# CM41x_M0 register map
Vendor: Analog Devices; Series: CM41x_M0; File version: 1p0
CPU: CM0 r0p0, little endian, MPU, FPU, 4 interrupt priority bits
Registers are 32-bit, read-write, reset 0x0 unless marked. A register's access mark holds for its fields unless they carry their own. Offsets are from the block's base; [hi:lo] are bit positions; {n}, {i} and the like mark numbered series; 'fields as' and 'values as' point back to an identical list.

## DWT1 — Data watchpoint unit
Base 0xE0001000
0x00 DWT_CTRL reset 0x20000000
  [31:28] NUMCOMP ro — Number of comparators.
0x1C DWT_PCSR
  [31:0] EIASAMPLE ro — Execution instruction address sample
0x20 DWT_COMP0
  [31:0] COMP range 0x00000000..0xFFFFFFFF — PC compare value
0x24 DWT_MASK0
  [3:0] MASK range 0x00000000..0x0000000F — Data Mask
0x28 DWT_FUNCTION0
  [3:0] FUNCTION range 0x00000000..0x0000000F — Function setting
0x30 DWT_COMP1
  [31:0] COMP range 0x00000000..0xFFFFFFFF — PC compare value
0x34 DWT_MASK1
  [3:0] MASK range 0x00000000..0x0000000F — Data Mask
0x38 DWT_FUNCTION1
  [3:0] FUNCTION range 0x00000000..0x0000000F — Function setting

## BKPT1 — Breakpoint unit
Base 0xE0002000
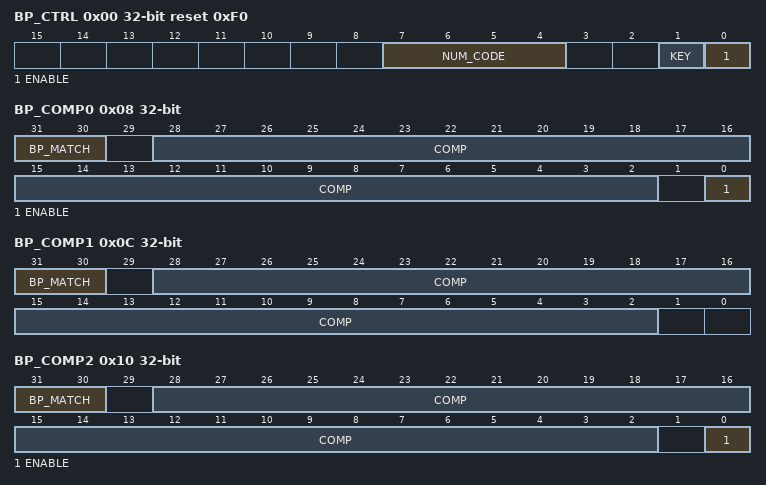
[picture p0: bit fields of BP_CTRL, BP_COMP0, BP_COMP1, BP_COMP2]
0x00 BP_CTRL reset 0xF0
  [7:4] NUM_CODE ro — Number of comparators.
  [1] KEY range 0x00000000..0x00000001
  [0] ENABLE range 0x00000000..0x00000001 — Breakpoint unit enable bit.
0x08 BP_COMP0
  [31:30] BP_MATCH range 0x00000000..0x00000003 — This selects what happens when the COMP address is matched
  [28:2] COMP range 0x00000000..0x07FFFFFF — Comparison address, UNKNOWN on reset.
  [0] ENABLE range 0x00000000..0x00000001 — Compare Enable
0x0C BP_COMP1
  [31:30] BP_MATCH range 0x00000000..0x00000003 — This selects what happens when the COMP address is matched
  [28:2] COMP range 0x00000000..0x07FFFFFF — Comparison address, UNKNOWN on reset.
0x10 BP_COMP2
  fields as BP_COMP0
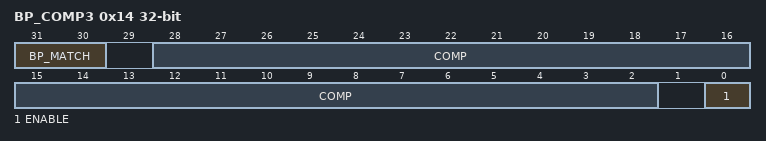
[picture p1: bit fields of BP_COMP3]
0x14 BP_COMP3
  fields as BP_COMP0

## SCS1 — NVIC and SysTick
Base 0xE000E000
0x08 ACTLR
  [31:0] ACTLR ro
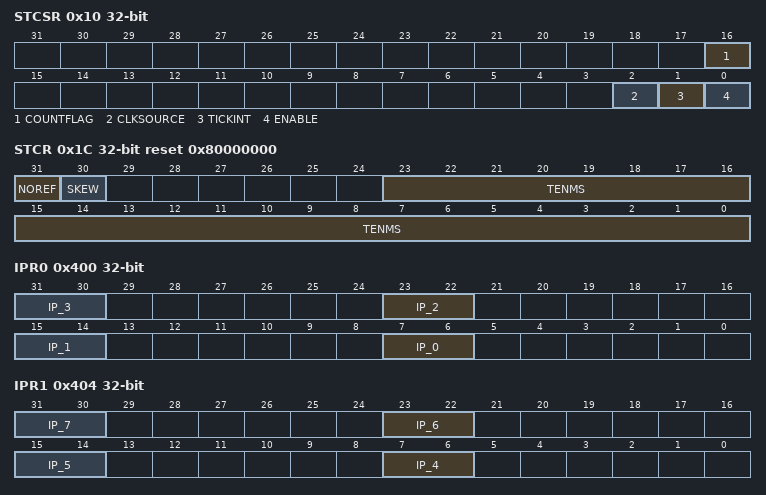
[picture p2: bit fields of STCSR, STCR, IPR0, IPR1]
0x10 STCSR
  [16] COUNTFLAG ro — Count down flag
  [2] CLKSOURCE ro — SysTick clock source.
  [1] TICKINT range 0x00000000..0x00000001 — Pend SysTick
  [0] ENABLE range 0x00000000..0x00000001 — Enable SysTick counter
0x14 STRVR
  [23:0] RELOAD range 0x00000000..0x00FFFFFF — Counter reload value
0x18 STCVR
  [23:0] CURRENT range 0x00000000..0x00FFFFFF — Current counter value
0x1C STCR reset 0x80000000
  [31] NOREF ro — Reference clock provided
  [30] SKEW ro — Calibration inexact
  [23:0] TENMS ro — Optional reload value
0x100 ISER
  [31:0] SETENA range 0x00000000..0xFFFFFFFF — Interrupt Enable
0x180 ICER
  [31:0] CLRENA range 0x00000000..0xFFFFFFFF — Interrupt Enable
0x200 ISPR
  [31:0] SETPEND range 0x00000000..0xFFFFFFFF — Set pending bit
0x280 ICPR
  [31:0] CLRPEND range 0x00000000..0xFFFFFFFF — Set pending bit
0x400 IPR0
  [8n+7:8n+6] IP_{n} range 0x00000000..0x00000003 (n=0..3) — Priority of interrupt {n}
0x404 IPR1
  [8n-25:8n-26] IP_{n} range 0x00000000..0x00000003 (n=4..7) — Priority of interrupt {n}
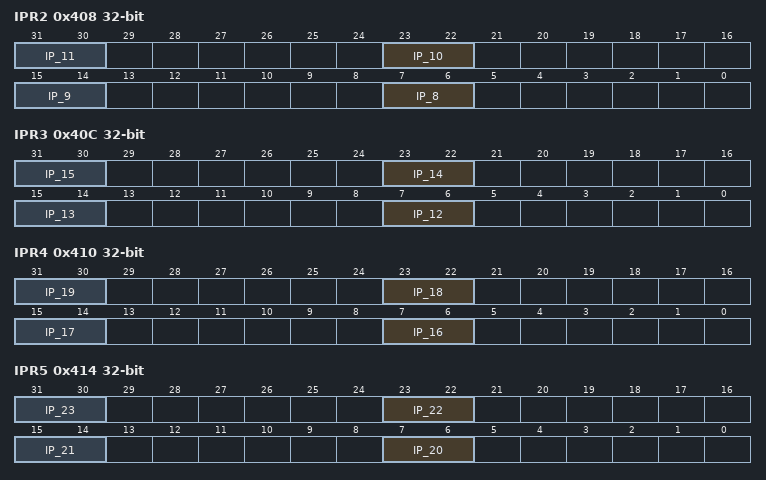
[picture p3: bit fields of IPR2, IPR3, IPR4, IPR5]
0x408 IPR2
  [8n-57:8n-58] IP_{n} range 0x00000000..0x00000003 (n=8..11) — Priority of interrupt {n}
0x40C IPR3
  [8n-89:8n-90] IP_{n} range 0x00000000..0x00000003 (n=12..15) — Priority of interrupt {n}
0x410 IPR4
  [8n-121:8n-122] IP_{n} range 0x00000000..0x00000003 (n=16..19) — Priority of interrupt {n}
0x414 IPR5
  [8n-153:8n-154] IP_{n} range 0x00000000..0x00000003 (n=20..23) — Priority of interrupt {n}
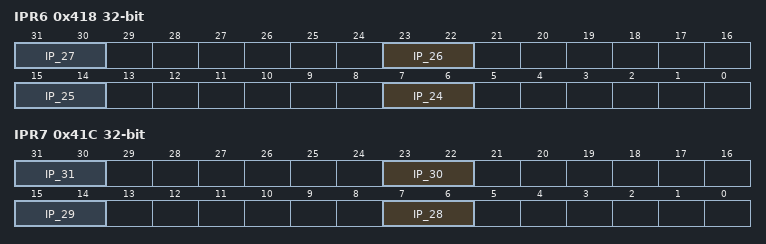
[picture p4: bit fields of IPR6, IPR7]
0x418 IPR6
  [8n-185:8n-186] IP_{n} range 0x00000000..0x00000003 (n=24..27) — Priority of interrupt {n}
0x41C IPR7
  [8n-217:8n-218] IP_{n} range 0x00000000..0x00000003 (n=28..31) — Priority of interrupt {n}

## SDCTRL — System and Debug Control
Base 0xE000ED00
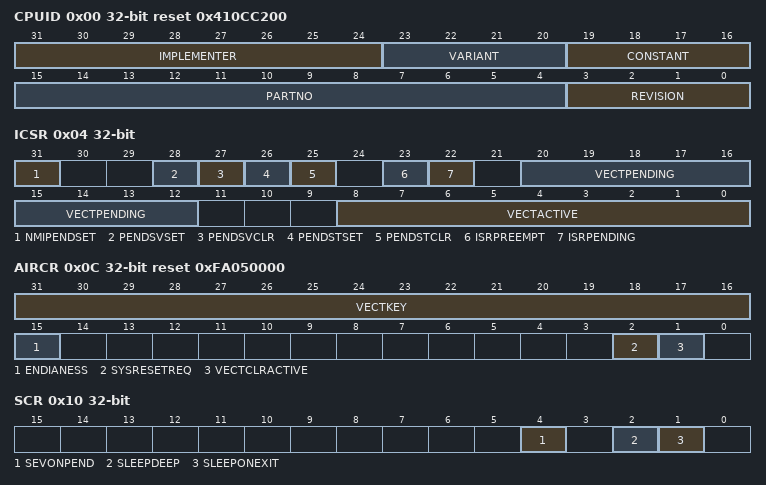
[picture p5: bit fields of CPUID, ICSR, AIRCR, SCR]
0x00 CPUID reset 0x410CC200 — CPU ID Base Register
  [31:24] IMPLEMENTER ro — Implementor code: 0x41 = ARM
  [23:20] VARIANT ro — Implementation defined variant number: 0x0 (for r0)
  [19:16] CONSTANT ro — Reads as 0xC
  [15:4] PARTNO ro — Number of processor within family: 0xC20
  [3:0] REVISION ro — Revision Number
0x04 ICSR — Interrupt Control State Register
  [31] NMIPENDSET range 0x00000000..0x00000001 — Set NMI
  [28] PENDSVSET range 0x00000000..0x00000001 — Set pending PendSV bit
  [27] PENDSVCLR range 0x00000000..0x00000001 — Clear pending PendSV bit
  [26] PENDSTSET range 0x00000000..0x00000001 — Set a pending SysTick bit
  [25] PENDSTCLR range 0x00000000..0x00000001 — Clear pending SysTick bit
  [23] ISRPREEMPT ro — Pending Interrupt
  [22] ISRPENDING ro — External interrupt pending flag
  [20:12] VECTPENDING ro — Highest pending exception
  [8:0] VECTACTIVE ro — Active exception number field
0x0C AIRCR reset 0xFA050000 — Application Interrupt and Reset Control Register
  [31:16] VECTKEY range 0x00000000..0x0000FFFF — Register key
  [15] ENDIANESS ro — Data endianness bit
  [2] SYSRESETREQ range 0x00000000..0x00000001 — Assert SYSRESETIRQ
  [1] VECTCLRACTIVE range 0x00000000..0x00000001 — Clear active state information
0x10 SCR — System Control Register
  [4] SEVONPEND range 0x00000000..0x00000001 — Wake on pend
  [2] SLEEPDEEP range 0x00000000..0x00000001 — Sleep deep bit.
  [1] SLEEPONEXIT range 0x00000000..0x00000001
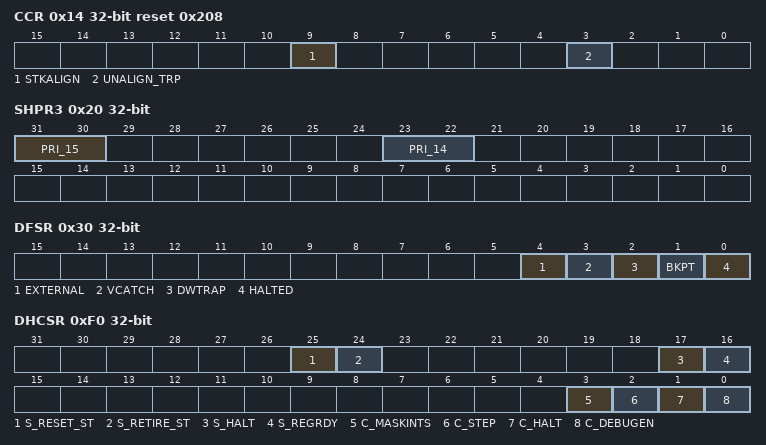
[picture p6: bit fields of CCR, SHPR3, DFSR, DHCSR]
0x14 CCR reset 0x208 — Configuration and Control Register
  [9] STKALIGN ro — Stack align
  [3] UNALIGN_TRP ro
0x1C SHPR2 — System Handler Priority Register 2
  [31:30] PRI_11 range 0x00000000..0x00000003 — Priority of system handler 11, SVCall
0x20 SHPR3 — System Handler Priority Register 3
  [31:30] PRI_15 range 0x00000000..0x00000003 — Priority of system handler 15, SysTick
  [23:22] PRI_14 range 0x00000000..0x00000003 — Priority of system handler 14, PendSV
0x24 SHCSR — System Handler Control and State Register
  [15] SVCALLPENDED range 0x00000000..0x00000001 — SVCall pending
0x30 DFSR — Debug Fault Status Register
  [4] EXTERNAL range 0x00000000..0x00000001 — External debug request flag
  [3] VCATCH range 0x00000000..0x00000001 — Vector catch flag
  [2] DWTRAP range 0x00000000..0x00000001 — Data Watchpoint (DW) flag.
  [1] BKPT range 0x00000000..0x00000001 — BKPT flag
  [0] HALTED range 0x00000000..0x00000001 — Halt request flag
0xF0 DHCSR — Debug Halting Control and Status Register
  [25] S_RESET_ST ro
  [24] S_RETIRE_ST ro
  [17] S_HALT ro — The core is halted in debug state only if S_HALT is set.
  [16] S_REGRDY ro
  [3] C_MASKINTS range 0x00000000..0x00000001
  [2] C_STEP range 0x00000000..0x00000001
  [1] C_HALT range 0x00000000..0x00000001
  [0] C_DEBUGEN range 0x00000000..0x00000001 — Enables or disable debug
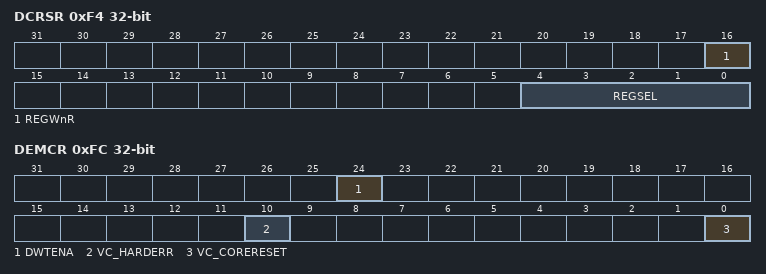
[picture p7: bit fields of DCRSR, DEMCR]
0xF4 DCRSR — Debug Core Register Selector Register
  [16] REGWnR range 0x00000000..0x00000001 — Register Write-not-Read
  [4:0] REGSEL range 0x00000000..0x0000001F — Select processor register
0xF8 DCRDR — Debug Core Register Data Register
  [31:0] VALUE range 0x00000000..0xFFFFFFFF
0xFC DEMCR — Debug Exception and Monitor Control Register
  [24] DWTENA range 0x00000000..0x00000001 — Global enable or disable for the DW unit
  [10] VC_HARDERR range 0x00000000..0x00000001 — Debug trap on a Hard Fault
  [0] VC_CORERESET range 0x00000000..0x00000001
